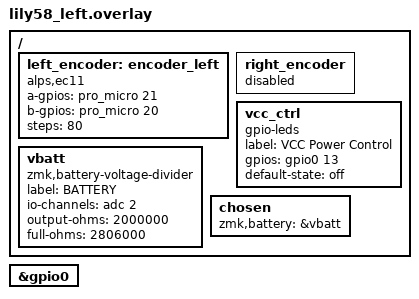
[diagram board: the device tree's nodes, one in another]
#include <dt-bindings/gpio/gpio.h>

/ {
    /* --- Encoder Configuration --- */
    left_encoder: encoder_left {
        compatible = "alps,ec11";
        a-gpios = <&pro_micro 21 (GPIO_ACTIVE_HIGH | GPIO_PULL_UP)>;
        b-gpios = <&pro_micro 20 (GPIO_ACTIVE_HIGH | GPIO_PULL_UP)>;
        steps = <80>;
        status = "okay"; /* Enabled on Left */
    };

    right_encoder: right_encoder {
        status = "disabled"; /* Disabled on Left */
    };

    /* --- SuperMini Power & Battery Fix --- */
    vbatt: vbatt {
        compatible = "zmk,battery-voltage-divider";
        label = "BATTERY";
        io-channels = <&adc 2>; /* Try 0, 1, or 2 if battery doesn't show */
        output-ohms = <2000000>;
        full-ohms = <2806000>;
    };

    vcc_ctrl: vcc_ctrl {
        compatible = "gpio-leds";
        label = "VCC Power Control";
        gpios = <&gpio0 13 GPIO_ACTIVE_HIGH>;
        default-state = "off"; /* Cuts power to peripherals on sleep */
    };

    chosen {
        zmk,battery = &vbatt;
    };
};

&gpio0 {
    status = "okay";
};   
